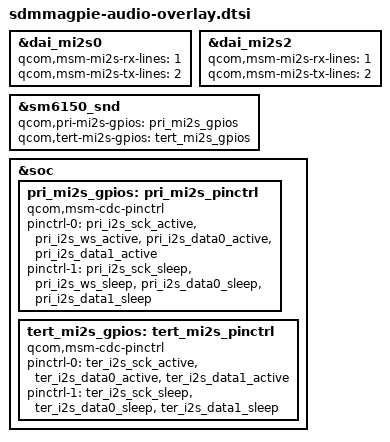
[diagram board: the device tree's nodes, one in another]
/*
 * Copyright (c) 2018, The Linux Foundation. All rights reserved.
 *
 * This program is free software; you can redistribute it and/or modify
 * it under the terms of the GNU General Public License version 2 and
 * only version 2 as published by the Free Software Foundation.
 *
 * This program is distributed in the hope that it will be useful,
 * but WITHOUT ANY WARRANTY; without even the implied warranty of
 * MERCHANTABILITY or FITNESS FOR A PARTICULAR PURPOSE.  See the
 * GNU General Public License for more details.
 */

#include "sm6150-audio-overlay.dtsi"
#include "d8d-spi-melon.dtsi"
/*
&swr0 {
	interrupts = <0 295 0>;
};

&swr1 {
	interrupts = <0 297 0>;
};

&swr2 {
	qcom,swr-wakeup-required = <0>;
	interrupts = <0 296 0>, <0 500 0>;
	interrupt-names = "swr_master_irq", "swr_wake_irq";
};*/
&dai_mi2s0{
			status = "okay";
			qcom,msm-mi2s-rx-lines = <1>;
			qcom,msm-mi2s-tx-lines = <2>;
	};

&dai_mi2s2{
			status = "okay";
			qcom,msm-mi2s-rx-lines = <1>;
			qcom,msm-mi2s-tx-lines = <2>;
		};

&sm6150_snd {
	qcom,pri-mi2s-gpios = <&pri_mi2s_gpios>;
	qcom,tert-mi2s-gpios= <&tert_mi2s_gpios>;
};
&soc {
	pri_mi2s_gpios: pri_mi2s_pinctrl {
		compatible = "qcom,msm-cdc-pinctrl";
 		pinctrl-names = "aud_active", "aud_sleep";
		pinctrl-0 = <&pri_i2s_sck_active &pri_i2s_ws_active &pri_i2s_data0_active
				&pri_i2s_data1_active>;
		pinctrl-1 = <&pri_i2s_sck_sleep &pri_i2s_ws_sleep &pri_i2s_data0_sleep
				&pri_i2s_data1_sleep>; 
 	};
	tert_mi2s_gpios: tert_mi2s_pinctrl {
		compatible = "qcom,msm-cdc-pinctrl";
 		pinctrl-names = "aud_active", "aud_sleep";
		pinctrl-0 = <&ter_i2s_sck_active &ter_i2s_data0_active
				&ter_i2s_data1_active>;
		pinctrl-1 = <&ter_i2s_sck_sleep &ter_i2s_data0_sleep
				&ter_i2s_data1_sleep>;
 	};
};
